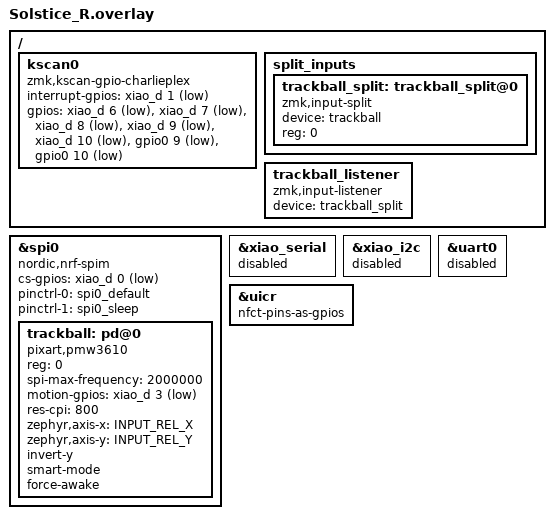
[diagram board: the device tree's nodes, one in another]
#include <dt-bindings/zmk/bt.h>
#include <input/processors.dtsi>
#include <dt-bindings/zmk/input_transform.h>
#include "Solstice_pinctrl_R.dtsi"

/ {
    kscan0: kscan0 {
        compatible = "zmk,kscan-gpio-charlieplex";
        interrupt-gpios = <&xiao_d 1 (GPIO_ACTIVE_LOW)>;
        gpios
            = <&xiao_d 6 (GPIO_ACTIVE_LOW)>
            , <&xiao_d 7 (GPIO_ACTIVE_LOW)>
            , <&xiao_d 8 (GPIO_ACTIVE_LOW)>
            , <&xiao_d 9 (GPIO_ACTIVE_LOW)>
            , <&xiao_d 10 (GPIO_ACTIVE_LOW)>
            , <&gpio0 9 GPIO_ACTIVE_LOW>
            , <&gpio0 10 GPIO_ACTIVE_LOW>
            ;
    };
};

&spi0 {
    status = "okay";
    cs-gpios =  <&xiao_d 0 GPIO_ACTIVE_LOW>;
    pinctrl-0 = <&spi0_default>;
    pinctrl-1 = <&spi0_sleep>;
    pinctrl-names = "default", "sleep";
    compatible = "nordic,nrf-spim";

    trackball: pd@0 {
        status = "okay";
        compatible = "pixart,pmw3610";
        reg = <0>;
        spi-max-frequency = <2000000>;
        motion-gpios = <&xiao_d 3 (GPIO_ACTIVE_LOW | GPIO_PULL_UP)>;
        res-cpi = <800>;
        zephyr,axis-x = <INPUT_REL_X>;
        zephyr,axis-y = <INPUT_REL_Y>;
        invert-y;
        smart-mode;
        force-awake;
    };
};

/ {
    split_inputs {
        #address-cells = <1>;
        #size-cells = <0>;

        trackball_split: trackball_split@0 {
            compatible = "zmk,input-split";
            device = <&trackball>;
            reg = <0>;
        };
    };

    trackball_listener: trackball_listener {
        compatible = "zmk,input-listener";
        device = <&trackball_split>;
    };
};

&xiao_serial { status = "disabled"; };
&xiao_i2c { status = "disabled"; };
&uart0 { status = "disabled";};

&uicr {
    nfct-pins-as-gpios;
};
